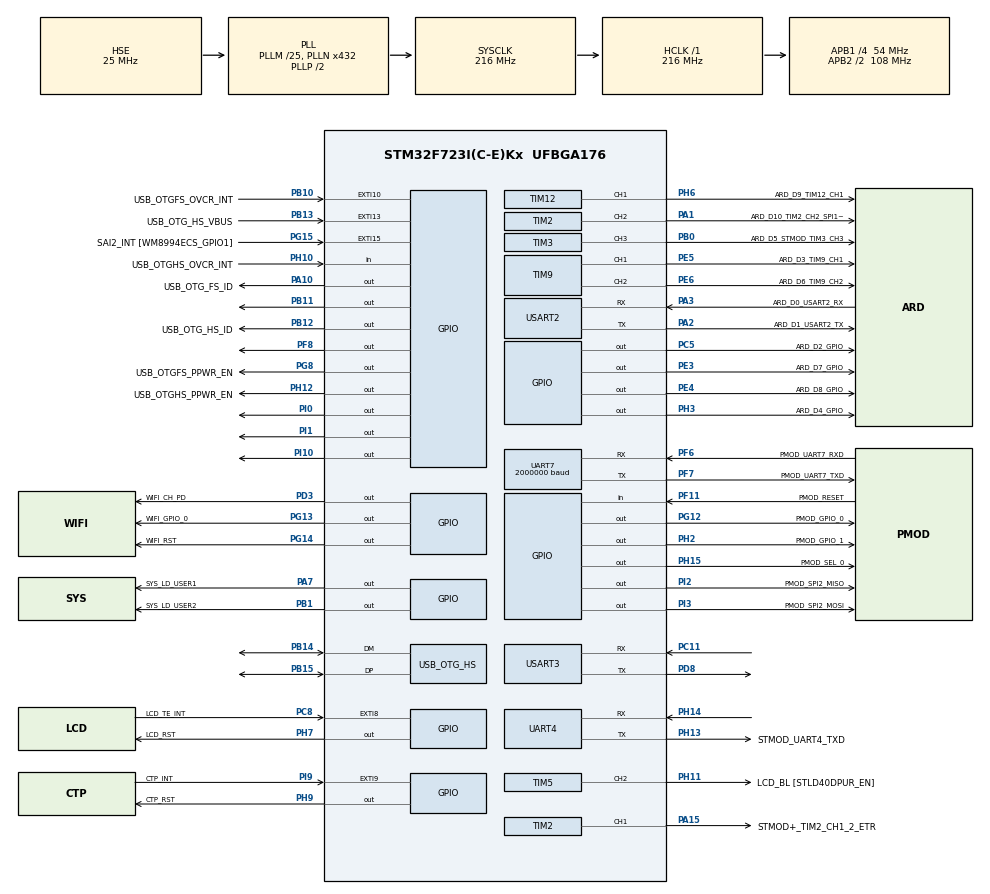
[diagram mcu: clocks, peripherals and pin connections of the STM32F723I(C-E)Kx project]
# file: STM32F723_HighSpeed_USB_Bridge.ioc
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CORTEX_M7.ART_ACCLERATOR_ENABLE=1
CORTEX_M7.CPU_DCache=Enabled
CORTEX_M7.CPU_ICache=Enabled
CORTEX_M7.PREFETCH_ENABLE=1
Dma.Request0=UART7_RX
Dma.Request1=USART3_RX
Dma.Request2=UART4_RX
Dma.Request3=USART2_RX
Dma.UART4_RX.2.Direction=DMA_PERIPH_TO_MEMORY
Dma.UART4_RX.2.FIFOMode=DMA_FIFOMODE_DISABLE
Dma.UART4_RX.2.Instance=DMA1_Stream2
Dma.UART4_RX.2.MemDataAlignment=DMA_MDATAALIGN_BYTE
Dma.UART4_RX.2.MemInc=DMA_MINC_ENABLE
Dma.UART4_RX.2.Mode=DMA_NORMAL
Dma.UART4_RX.2.PeriphDataAlignment=DMA_PDATAALIGN_BYTE
Dma.UART4_RX.2.PeriphInc=DMA_PINC_DISABLE
Dma.UART4_RX.2.Priority=DMA_PRIORITY_MEDIUM
Dma.UART7_RX.0.Direction=DMA_PERIPH_TO_MEMORY
Dma.UART7_RX.0.FIFOMode=DMA_FIFOMODE_ENABLE
Dma.UART7_RX.0.FIFOThreshold=DMA_FIFO_THRESHOLD_FULL
Dma.UART7_RX.0.Instance=DMA1_Stream3
Dma.UART7_RX.0.MemBurst=DMA_MBURST_SINGLE
Dma.UART7_RX.0.MemDataAlignment=DMA_MDATAALIGN_BYTE
Dma.UART7_RX.0.MemInc=DMA_MINC_ENABLE
Dma.UART7_RX.0.Mode=DMA_NORMAL
Dma.UART7_RX.0.PeriphBurst=DMA_PBURST_SINGLE
Dma.UART7_RX.0.PeriphDataAlignment=DMA_PDATAALIGN_BYTE
Dma.UART7_RX.0.PeriphInc=DMA_PINC_DISABLE
Dma.UART7_RX.0.Priority=DMA_PRIORITY_VERY_HIGH
Dma.USART2_RX.3.Direction=DMA_PERIPH_TO_MEMORY
Dma.USART2_RX.3.FIFOMode=DMA_FIFOMODE_DISABLE
Dma.USART2_RX.3.Instance=DMA1_Stream5
Dma.USART2_RX.3.MemDataAlignment=DMA_MDATAALIGN_BYTE
Dma.USART2_RX.3.MemInc=DMA_MINC_ENABLE
Dma.USART2_RX.3.Mode=DMA_NORMAL
Dma.USART2_RX.3.PeriphDataAlignment=DMA_PDATAALIGN_BYTE
Dma.USART2_RX.3.PeriphInc=DMA_PINC_DISABLE
Dma.USART2_RX.3.Priority=DMA_PRIORITY_LOW
Dma.USART3_RX.1.Direction=DMA_PERIPH_TO_MEMORY
Dma.USART3_RX.1.FIFOMode=DMA_FIFOMODE_DISABLE
Dma.USART3_RX.1.Instance=DMA1_Stream1
Dma.USART3_RX.1.MemDataAlignment=DMA_MDATAALIGN_BYTE
Dma.USART3_RX.1.MemInc=DMA_MINC_ENABLE
Dma.USART3_RX.1.Mode=DMA_NORMAL
Dma.USART3_RX.1.PeriphDataAlignment=DMA_PDATAALIGN_BYTE
Dma.USART3_RX.1.PeriphInc=DMA_PINC_DISABLE
Dma.USART3_RX.1.Priority=DMA_PRIORITY_HIGH
Mcu.Family=STM32F7
Mcu.Name=STM32F723I(C-E)Kx
Mcu.Package=UFBGA176
NVIC.DMA1_Stream1_IRQn=true\:1\:1\:true\:false\:true\:false\:false
NVIC.DMA1_Stream2_IRQn=true\:1\:2\:true\:false\:true\:false\:false
NVIC.DMA1_Stream3_IRQn=true\:1\:0\:true\:false\:true\:false\:false
NVIC.DMA1_Stream5_IRQn=true\:1\:3\:true\:false\:true\:false\:false
NVIC.OTG_HS_IRQn=true\:3\:0\:true\:false\:true\:true\:true
NVIC.PriorityGroup=NVIC_PRIORITYGROUP_2
NVIC.TIM1_UP_TIM10_IRQn=true\:3\:3\:true\:false\:true\:true\:true
NVIC.TIM8_TRG_COM_TIM14_IRQn=true\:0\:0\:false\:false\:true\:true\:false
NVIC.TimeBase=TIM1_UP_TIM10_IRQn
NVIC.TimeBaseIP=TIM1
NVIC.UART7_IRQn=true\:2\:0\:true\:false\:true\:true\:false
PA0-WKUP.GPIO_Label=SYS_B_User
PA0-WKUP.Mode=SYS_WakeUp0
PA0-WKUP.Signal=SYS_WKUP1
PA1.GPIO_Label=ARD_D10_TIM2_CH2_SPI1_NSS
PA1.Signal=S_TIM2_CH2
PA10.GPIO_Label=USB_OTG_FS_ID
PA10.Signal=GPIO_Output
PA11.Signal=USB_OTG_FS_DM
PA12.Signal=USB_OTG_FS_DP
PA13.Mode=Serial_Wire
PA13.Signal=SYS_JTMS-SWDIO
PA14.Mode=Serial_Wire
PA14.Signal=SYS_JTCK-SWCLK
PA15.GPIO_Label=STMOD+_TIM2_CH1_2_ETR
PA15.Signal=S_TIM2_CH1_ETR
PA2.GPIO_Label=ARD_D1_USART2_TX
PA2.Mode=Asynchronous
PA2.Signal=USART2_TX
PA3.GPIO_Label=ARD_D0_USART2_RX
PA3.Mode=Asynchronous
PA3.Signal=USART2_RX
PA4.GPIO_Label=ARD_A1
PA4.Signal=ADCx_IN4
PA5.GPIO_Label=ARD_D13_SPI1_SCK
PA5.Signal=SPI1_SCK
PA6.GPIO_Label=ARD_A0
PA6.Signal=ADCx_IN6
PA7.GPIO_Label=SYS_LD_USER1
PA7.Signal=GPIO_Output
PA8.GPIO_Label=CTP_SCL
PA8.Signal=I2C3_SCL
PA9.Signal=USB_OTG_FS_VBUS
PB0.GPIO_Label=ARD_D5_STMOD_TIM3_CH3
PB0.Signal=S_TIM3_CH3
PB1.GPIO_Label=SYS_LD_USER2
PB1.Signal=GPIO_Output
PB10.GPIO_Label=USB_OTGFS_OVCR_INT
PB10.Signal=GPXTI10
PB11.Signal=GPIO_Output
PB12.GPIO_Label=USB_OTG_HS_ID
PB12.Signal=GPIO_Output
PB13.GPIO_Label=USB_OTG_HS_VBUS
PB13.Signal=GPXTI13
PB14.Mode=Internal_Phy_Device
PB14.Signal=USB_OTG_HS_DM
PB15.Mode=Internal_Phy_Device
PB15.Signal=USB_OTG_HS_DP
PB2.GPIO_Label=QSPI_CLK [MX25L51245G_SCLK]
PB2.Signal=QUADSPI_CLK
PB3.GPIO_Label=SYS_STLINK_JTDO_SWO
PB3.Signal=SYS_JTDO-SWO
PB4.GPIO_Label=ARD_D12_SPI1_MISO
PB4.Signal=SPI1_MISO
PB5.GPIO_Label=ARD_D11_TIM3_CH2_SPI1_MOSI
PB5.Signal=SPI1_MOSI
PB6.GPIO_Label=QSPI_NCS [MX25L51245G_CS]
PB6.Signal=QUADSPI_BK1_NCS
PB7.GPIO_Label=NC1
PB7.Signal=FMC_NL
PB8.GPIO_Label=SAI2_I2C1_SCL [WM8994ECS/R_SCLK]
PB8.Signal=I2C1_SCL
PB9.GPIO_Label=SAI2_I2C1_SDA [WM8994ECS_SDA]
PB9.Signal=I2C1_SDA
PC0.GPIO_Label=ARD_A4
PC0.Signal=ADCx_IN10
PC1.GPIO_Label=ARD_A5
PC1.Signal=ADCx_IN11
PC10.GPIO_Label=QSPI_D1 [MX25L51245G_SIO1]
PC10.Signal=QUADSPI_BK1_IO1
PC11.Mode=Asynchronous
PC11.Signal=USART3_RX
PC12.GPIO_Label=UART_TXD_WIFI_RX
PC12.Signal=UART5_TX
PC14-OSC32_IN.Mode=LSE-External-Oscillator
PC14-OSC32_IN.Signal=RCC_OSC32_IN
PC15-OSC32_OUT.Mode=LSE-External-Oscillator
PC15-OSC32_OUT.Signal=RCC_OSC32_OUT
PC2.GPIO_Label=STMOD_SPI2_MISOs
PC2.Signal=SPI2_MISO
PC3.GPIO_Label=STMOD+_SPI2_MOSIs
PC3.Signal=SPI2_MOSI
PC4.GPIO_Label=ARD_A2
PC4.Signal=ADCx_IN14
PC5.GPIO_Label=ARD_D2_GPIO
PC5.Signal=GPIO_Output
PC6.GPIO_Label=VCP_TX [STM32F103CBT6_PA3]
PC6.Signal=USART6_TX
PC7.GPIO_Label=VCP_RX [STM32F103CBT6_PA2]
PC7.Signal=USART6_RX
PC8.GPIO_Label=LCD_TE_INT
PC8.Signal=GPXTI8
PC9.GPIO_Label=QSPI_D0 [MX25L51245G_SIO0]
PC9.Signal=QUADSPI_BK1_IO0
PD0.GPIO_Label=LCD_PSRAM_D2
PD0.Signal=FMC_D2_DA2
PD1.GPIO_Label=LCD_PSRAM_D3
PD1.Signal=FMC_D3_DA3
PD10.GPIO_Label=LCD_PSRAM_D15
PD10.Signal=FMC_D15_DA15
PD11.GPIO_Label=PSRAM_A16
PD11.Signal=FMC_A16_CLE
PD12.GPIO_Label=PSRAM_A17
PD12.Signal=FMC_A17_ALE
PD13.GPIO_Label=QSPI_D3 [MX25L51245G_SIO3]
PD13.Signal=QUADSPI_BK1_IO3
PD14.GPIO_Label=LCD_PSRAM_D0
PD14.Signal=FMC_D0_DA0
PD15.GPIO_Label=LCD_PSRAM_D1
PD15.Signal=FMC_D1_DA1
PD2.GPIO_Label=UART_RXD_WIFI_TX
PD2.Signal=UART5_RX
PD3.GPIO_Label=WIFI_CH_PD
PD3.Signal=GPIO_Output
PD4.GPIO_Label=LCD_PSRAM_NWE
PD4.Signal=FMC_NOE
PD5.GPIO_Label=LCD_PSRAM_NWE
PD5.Signal=FMC_NWE
PD7.GPIO_Label=PSRAM_NE1 [IS66WV51216EBLL_CS1]
PD7.Signal=FMC_NE1
PD8.Mode=Asynchronous
PD8.Signal=USART3_TX
PD9.GPIO_Label=LCD_PSRAM_D14
PD9.Signal=FMC_D14_DA14
PE0.GPIO_Label=PSRAM_NBL0 [IS66WV51216EBLL_LB]
PE0.Signal=FMC_NBL0
PE1.GPIO_Label=PSRAM_NBL1 [IS66WV51216EBLL_UB]
PE1.Signal=FMC_NBL1
PE10.GPIO_Label=LCD_PSRAM_D7
PE10.Signal=FMC_D7_DA7
PE11.GPIO_Label=LCD_PSRAM_D8
PE11.Signal=FMC_D8_DA8
PE12.GPIO_Label=LCD_PSRAM_D9
PE12.Signal=FMC_D9_DA9
PE13.GPIO_Label=LCD_PSRAM_D10
PE13.Signal=FMC_D10_DA10
PE14.GPIO_Label=LCD_PSRAM_D11
PE14.Signal=FMC_D11_DA11
PE15.GPIO_Label=LCD_PSRAM_D12
PE15.Signal=FMC_D12_DA12
PE2.GPIO_Label=QSPI_D2 [MX25L51245G_SIO2]
PE2.Signal=QUADSPI_BK1_IO2
PE3.GPIO_Label=ARD_D7_GPIO
PE3.Signal=GPIO_Output
PE4.GPIO_Label=ARD_D8_GPIO
PE4.Signal=GPIO_Output
PE5.GPIO_Label=ARD_D3_TIM9_CH1
PE5.Signal=S_TIM9_CH1
PE6.GPIO_Label=ARD_D6_TIM9_CH2
PE6.Signal=S_TIM9_CH2
PE7.GPIO_Label=LCD_PSRAM_D4
PE7.Signal=FMC_D4_DA4
PE8.GPIO_Label=LCD_PSRAM_D5
PE8.Signal=FMC_D5_DA5
PE9.GPIO_Label=LCD_PSRAM_D6
PE9.Signal=FMC_D6_DA6
PF0.GPIO_Label=PSRAM_A0
PF0.Signal=FMC_A0
PF1.GPIO_Label=PSRAM_A1
PF1.Signal=FMC_A1
PF10.GPIO_Label=ARD_A3_ADC3_IN8
PF10.Signal=ADC3_IN8
PF11.GPIO_Label=PMOD_RESET
PF11.Signal=GPIO_Input
PF12.GPIO_Label=PSRAM_A6
PF12.Signal=FMC_A6
PF13.GPIO_Label=PSRAM_A7
PF13.Signal=FMC_A7
PF14.GPIO_Label=PSRAM_A8
PF14.Signal=FMC_A8
PF15.GPIO_Label=PSRAM_A9
PF15.Signal=FMC_A9
PF2.GPIO_Label=PSRAM_A2
PF2.Signal=FMC_A2
PF3.GPIO_Label=PSRAM_A3
PF3.Signal=FMC_A3
PF4.GPIO_Label=PSRAM_A4
PF4.Signal=FMC_A4
PF5.GPIO_Label=PSRAM_A5
PF5.Signal=FMC_A5
PF6.GPIO_Label=PMOD_UART7_RXD
PF6.GPIO_PuPd=GPIO_PULLUP
PF6.Mode=Asynchronous
PF6.Signal=UART7_RX
PF7.GPIO_Label=PMOD_UART7_TXD
PF7.GPIO_PuPd=GPIO_PULLUP
PF7.Mode=Asynchronous
PF7.Signal=UART7_TX
PF8.Signal=GPIO_Output
PF9.GPIO_Label=PMOD_UART7_CTS
PF9.Signal=UART7_CTS
PG0.GPIO_Label=PSRAM_A10
PG0.Signal=FMC_A10
PG1.GPIO_Label=PSRAM_A11
PG1.Signal=FMC_A11
PG10.GPIO_Label=SAI2_SD_B [SAI2_SD_B_ADCDAT1]
PG10.Signal=SAI2_SD_B
PG12.GPIO_Label=PMOD_GPIO_0
PG12.Signal=GPIO_Output
PG13.GPIO_Label=WIFI_GPIO_0
PG13.Signal=GPIO_Output
PG14.GPIO_Label=WIFI_RST
PG14.Signal=GPIO_Output
PG15.GPIO_Label=SAI2_INT [WM8994ECS_GPIO1]
PG15.Signal=GPXTI15
PG2.GPIO_Label=PSRAM_A12
PG2.Signal=FMC_A12
PG3.GPIO_Label=PSRAM_A13
PG3.Signal=FMC_A13
PG4.GPIO_Label=PSRAM_A14
PG4.Signal=FMC_A14_BA0
PG5.GPIO_Label=PSRAM_A15
PG5.Signal=FMC_A15_BA1
PG8.GPIO_Label=USB_OTGFS_PPWR_EN
PG8.Signal=GPIO_Output
PG9.GPIO_Label=LCD_NE
PG9.Signal=FMC_NE2
PH0-OSC_IN.Mode=HSE-External-Oscillator
PH0-OSC_IN.Signal=RCC_OSC_IN
PH1-OSC_OUT.Mode=HSE-External-Oscillator
PH1-OSC_OUT.Signal=RCC_OSC_OUT
PH10.GPIO_Label=USB_OTGHS_OVCR_INT
PH10.Signal=GPIO_Input
PH11.GPIO_Label=LCD_BL [STLD40DPUR_EN]
PH11.Signal=S_TIM5_CH2
PH12.GPIO_Label=USB_OTGHS_PPWR_EN
PH12.Signal=GPIO_Output
PH13.GPIO_Label=STMOD_UART4_TXD
PH13.Mode=Asynchronous
PH13.Signal=UART4_TX
PH14.Mode=Asynchronous
PH14.Signal=UART4_RX
PH15.GPIO_Label=PMOD_SEL_0
PH15.PinState=GPIO_PIN_SET
PH15.Signal=GPIO_Output
PH2.GPIO_Label=PMOD_GPIO_1
PH2.Signal=GPIO_Output
PH3.GPIO_Label=ARD_D4_GPIO
PH3.Signal=GPIO_Output
PH4.GPIO_Label=ARD_D15_STMOD_I2C2_SCL
PH4.Signal=I2C2_SCL
PH5.GPIO_Label=ARD_D14_STMOD_I2C2_SDA
PH5.Signal=I2C2_SDA
PH6.GPIO_Label=ARD_D9_TIM12_CH1
PH6.Signal=S_TIM12_CH1
PH7.GPIO_Label=LCD_RST
PH7.Signal=GPIO_Output
PH8.GPIO_Label=CTP_SDA
PH8.Signal=I2C3_SDA
PH9.GPIO_Label=CTP_RST
PH9.Signal=GPIO_Output
PI0.Signal=GPIO_Output
PI1.Signal=GPIO_Output
PI10.Signal=GPIO_Output
PI2.GPIO_Label=PMOD_SPI2_MISO
PI2.Signal=GPIO_Output
PI3.GPIO_Label=PMOD_SPI2_MOSI
PI3.Signal=GPIO_Output
PI4.GPIO_Label=SAI2_MCLK_A [WM8994ECS_MCLK1]
PI4.Signal=SAI2_MCLK_A
PI5.GPIO_Label=SAI2_SCK_A [WM8994ECS_BCLK1]
PI5.Signal=SAI2_SCK_A
PI6.GPIO_Label=SAI2_SD_A [WM8994ECS_DACDAT1]
PI6.Signal=SAI2_SD_A
PI7.GPIO_Label=SAI2_FS_A [WM8994ECS_LRCLK1]
PI7.Signal=SAI2_FS_A
PI9.GPIO_Label=CTP_INT
PI9.Signal=GPXTI9
ProjectManager.HeapSize=0x400
ProjectManager.StackSize=0x400
ProjectManager.TargetToolchain=MDK-ARM V5
RCC.AHBFreq_Value=216000000
RCC.APB1CLKDivider=RCC_HCLK_DIV4
RCC.APB1Freq_Value=54000000
RCC.APB1TimFreq_Value=108000000
RCC.APB2CLKDivider=RCC_HCLK_DIV2
RCC.APB2Freq_Value=108000000
RCC.APB2TimFreq_Value=216000000
RCC.CortexFreq_Value=216000000
RCC.HCLKFreq_Value=216000000
RCC.HSE_VALUE=25000000
RCC.HSI_VALUE=16000000
RCC.PLLM=25
RCC.PLLN=432
RCC.PLLQ=9
RCC.SYSCLKFreq_VALUE=216000000
RCC.SYSCLKSource=RCC_SYSCLKSOURCE_PLLCLK
RCC.UART4CLockSelection=RCC_UART4CLKSOURCE_SYSCLK
RCC.UART5CLockSelection=RCC_UART5CLKSOURCE_SYSCLK
RCC.UART7CLockSelection=RCC_UART7CLKSOURCE_SYSCLK
RCC.USART2CLockSelection=RCC_USART2CLKSOURCE_SYSCLK
RCC.USART6CLockSelection=RCC_USART6CLKSOURCE_SYSCLK
RCC.USBFreq_Value=48000000
RCC.VCOOutputFreq_Value=432000000
REXTPHYHS.GPIO_Label=REXT_OTGPHY
REXTPHYHS.Mode=Internal_Phy_Device
REXTPHYHS.Signal=USB_OTG_HS_REXTPHYHS
SH.ADCx_IN10.0=ADC1_IN10
SH.ADCx_IN10.1=ADC2_IN10
SH.ADCx_IN11.0=ADC1_IN11
SH.ADCx_IN11.1=ADC2_IN11
SH.ADCx_IN14.0=ADC1_IN14
SH.ADCx_IN14.1=ADC2_IN14
SH.ADCx_IN4.0=ADC1_IN4
SH.ADCx_IN4.1=ADC2_IN4
SH.ADCx_IN6.0=ADC1_IN6
SH.ADCx_IN6.1=ADC2_IN6
SH.FMC_A0.0=FMC_A0
SH.FMC_A1.0=FMC_A1
SH.FMC_A10.0=FMC_A10
SH.FMC_A11.0=FMC_A11
SH.FMC_A12.0=FMC_A12
SH.FMC_A13.0=FMC_A13
SH.FMC_A14_BA0.0=FMC_A14
SH.FMC_A15_BA1.0=FMC_A15
SH.FMC_A16_CLE.0=FMC_A16
SH.FMC_A17_ALE.0=FMC_A17
SH.FMC_A2.0=FMC_A2
SH.FMC_A3.0=FMC_A3
SH.FMC_A4.0=FMC_A4
SH.FMC_A5.0=FMC_A5
SH.FMC_A6.0=FMC_A6
SH.FMC_A7.0=FMC_A7
SH.FMC_A8.0=FMC_A8
SH.FMC_A9.0=FMC_A9
SH.FMC_D0_DA0.0=FMC_D0
SH.FMC_D10_DA10.0=FMC_D10
SH.FMC_D11_DA11.0=FMC_D11
SH.FMC_D12_DA12.0=FMC_D12
SH.FMC_D14_DA14.0=FMC_D14
SH.FMC_D15_DA15.0=FMC_D15
SH.FMC_D1_DA1.0=FMC_D1
SH.FMC_D2_DA2.0=FMC_D2
SH.FMC_D3_DA3.0=FMC_D3
SH.FMC_D4_DA4.0=FMC_D4
SH.FMC_D5_DA5.0=FMC_D5
SH.FMC_D6_DA6.0=FMC_D6
SH.FMC_D7_DA7.0=FMC_D7
SH.FMC_D8_DA8.0=FMC_D8
SH.FMC_D9_DA9.0=FMC_D9
SH.FMC_NBL0.0=FMC_NBL0
SH.FMC_NBL1.0=FMC_NBL1
SH.FMC_NL.0=FMC_NL
SH.FMC_NOE.0=FMC_NOE
SH.FMC_NWE.0=FMC_NWE
SH.S_TIM12_CH1.0=TIM12_CH1,PWM Generation1 CH1
SH.S_TIM2_CH1_ETR.0=TIM2_CH1,PWM Generation1 CH1
SH.S_TIM2_CH2.0=TIM2_CH2,PWM Generation2 CH2
SH.S_TIM3_CH3.0=TIM3_CH3,PWM Generation3 CH3
SH.S_TIM5_CH2.0=TIM5_CH2,PWM Generation2 CH2
SH.S_TIM9_CH1.0=TIM9_CH1,PWM Generation1 CH1
SH.S_TIM9_CH2.0=TIM9_CH2,PWM Generation2 CH2
TIM12.Channel-PWM\ Generation1\ CH1=TIM_CHANNEL_1
TIM14.AutoReloadPreload=TIM_AUTORELOAD_PRELOAD_ENABLE
TIM14.Period=1999
TIM14.Prescaler=21599
TIM2.Channel-PWM\ Generation1\ CH1=TIM_CHANNEL_1
TIM2.Channel-PWM\ Generation2\ CH2=TIM_CHANNEL_2
TIM3.Channel-PWM\ Generation3\ CH3=TIM_CHANNEL_3
TIM5.Channel-PWM\ Generation2\ CH2=TIM_CHANNEL_2
TIM9.Channel-PWM\ Generation1\ CH1=TIM_CHANNEL_1
TIM9.Channel-PWM\ Generation2\ CH2=TIM_CHANNEL_2
UART7.BaudRate=2000000
UART7.RxPinLevelInvertParam=UART_ADVFEATURE_RXINV_DISABLE
USART2.VirtualMode-Asynchronous=VM_ASYNC
USART3.VirtualMode-Asynchronous=VM_ASYNC
USB_DEVICE.CLASS_NAME_HS=CDC
USB_DEVICE.USBD_LPM_ENABLED-CDC_HS=0
USB_DEVICE.VirtualMode-CDC_HS=Cdc
USB_DEVICE.VirtualModeHS=Cdc_HS
USB_OTG_HS.VirtualMode=Int_Phy_Device
VP_SYS_VS_tim1.Mode=TIM1
VP_TIM14_VS_ClockSourceINT.Mode=Enable_Timer
VP_USB_DEVICE_VS_USB_DEVICE_CDC_HS.Mode=CDC_HS
board=32F723EDISCOVERY

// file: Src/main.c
/* USER CODE BEGIN Header */
/**
  ******************************************************************************
  * @file           : main.c
  * @brief          : Main program body
  ******************************************************************************
  * This notice applies to any and all portions of this file
  * that are not between comment pairs USER CODE BEGIN and
  * USER CODE END. Other portions of this file, whether
  * inserted by the user or by software development tools
  * are owned by their respective copyright owners.
  *
  * Copyright (c) 2019 STMicroelectronics International N.V.
  * All rights reserved.
  *
  * Redistribution and use in source and binary forms, with or without
  * modification, are permitted, provided that the following conditions are met:
  *
  * 1. Redistribution of source code must retain the above copyright notice,
  *    this list of conditions and the following disclaimer.
  * 2. Redistributions in binary form must reproduce the above copyright notice,
  *    this list of conditions and the following disclaimer in the documentation
  *    and/or other materials provided with the distribution.
  * 3. Neither the name of STMicroelectronics nor the names of other
  *    contributors to this software may be used to endorse or promote products
  *    derived from this software without specific written permission.
  * 4. This software, including modifications and/or derivative works of this
  *    software, must execute solely and exclusively on microcontroller or
  *    microprocessor devices manufactured by or for STMicroelectronics.
  * 5. Redistribution and use of this software other than as permitted under
  *    this license is void and will automatically terminate your rights under
  *    this license.
  *
  * THIS SOFTWARE IS PROVIDED BY STMICROELECTRONICS AND CONTRIBUTORS "AS IS"
  * AND ANY EXPRESS, IMPLIED OR STATUTORY WARRANTIES, INCLUDING, BUT NOT
  * LIMITED TO, THE IMPLIED WARRANTIES OF MERCHANTABILITY, FITNESS FOR A
  * PARTICULAR PURPOSE AND NON-INFRINGEMENT OF THIRD PARTY INTELLECTUAL PROPERTY
  * RIGHTS ARE DISCLAIMED TO THE FULLEST EXTENT PERMITTED BY LAW. IN NO EVENT
  * SHALL STMICROELECTRONICS OR CONTRIBUTORS BE LIABLE FOR ANY DIRECT, INDIRECT,
  * INCIDENTAL, SPECIAL, EXEMPLARY, OR CONSEQUENTIAL DAMAGES (INCLUDING, BUT NOT
  * LIMITED TO, PROCUREMENT OF SUBSTITUTE GOODS OR SERVICES; LOSS OF USE, DATA,
  * OR PROFITS; OR BUSINESS INTERRUPTION) HOWEVER CAUSED AND ON ANY THEORY OF
  * LIABILITY, WHETHER IN CONTRACT, STRICT LIABILITY, OR TORT (INCLUDING
  * NEGLIGENCE OR OTHERWISE) ARISING IN ANY WAY OUT OF THE USE OF THIS SOFTWARE,
  * EVEN IF ADVISED OF THE POSSIBILITY OF SUCH DAMAGE.
  *
  ******************************************************************************
  */
/* USER CODE END Header */

#include "main.h"
#include "usb_device.h"

/* USER CODE BEGIN Includes */
#include "dataMGR.h"
#include "CE32_ioncom.h"
#include "usbd_cdc_if.h"

#define CDC_BUF_SIZE 0x2000
/* USER CODE END Includes */

TIM_HandleTypeDef htim2;
TIM_HandleTypeDef htim3;
TIM_HandleTypeDef htim5;
TIM_HandleTypeDef htim9;
TIM_HandleTypeDef htim12;
TIM_HandleTypeDef htim14;

UART_HandleTypeDef huart4;
UART_HandleTypeDef huart7;
UART_HandleTypeDef huart2;
UART_HandleTypeDef huart3;
DMA_HandleTypeDef hdma_uart4_rx;
DMA_HandleTypeDef hdma_uart7_rx;
DMA_HandleTypeDef hdma_usart2_rx;
DMA_HandleTypeDef hdma_usart3_rx;

/* USER CODE BEGIN PV */
int Bytes;
int Nfail;
int retries;
int WaitCyc;
uint8_t data_buf_RX1[BUF_SIZE];		// This records @ 20kHz x 32CH
uint8_t data_buf_RX2[BUF_SIZE];		// This records @ 20kHz x 32CH
uint8_t data_buf_RX3[BUF_SIZE];		// This records @ 20kHz x 32CH
uint8_t data_buf_RX4[BUF_SIZE];		// This records @ 20kHz x 32CH
uint8_t data_buf_TX[BUF_SIZE];		// This records @ 20kHz x 32CH
uint8_t data_buf_RX_CDC[CDC_BUF_SIZE];
uint16_t misc_DigiSig;
uint8_t rec_cnt;
uint32_t log_cnt;
uint32_t test;
uint32_t LED_CNT;
uint32_t logIdx;	//Index of log in the CE32_systemLog struct
uint32_t filePTR;	//recording pointer location (in 512B unit,real filelen=512*x)
uint32_t updHeader;
dataMGR MGR_TX;
dataMGR MGR_RX1;
dataMGR MGR_RX2;
dataMGR MGR_RX3;
dataMGR MGR_RX4;
dataMGR MGR_CDC;
dataMGR MGR_prev;
dataMGR MGR_misc;
dataMGR MGR_cmd;
uint8_t HD32_sd_temp;

//dataMGR PMGR;
int freq;

const uint16_t RX_size=1000;

struct CE32_IONCOM_Handle IC_handle1;
struct CE32_IONCOM_Handle IC_handle2;
struct CE32_IONCOM_Handle IC_handle3;
struct CE32_IONCOM_Handle IC_handle4;

extern USBD_HandleTypeDef hUsbDeviceFS;
/* USER CODE END PV */

void SystemClock_Config(void);
static void MX_GPIO_Init(void);
static void MX_DMA_Init(void);
static void MX_TIM2_Init(void);
static void MX_TIM3_Init(void);
static void MX_TIM5_Init(void);
static void MX_TIM9_Init(void);
static void MX_TIM12_Init(void);
static void MX_UART7_Init(void);
static void MX_UART4_Init(void);
static void MX_USART2_UART_Init(void);
static void MX_USART3_UART_Init(void);
static void MX_TIM14_Init(void);

int main(void)
{

  /* Enable I-Cache---------------------------------------------------------*/
  SCB_EnableICache();

  /* Enable D-Cache---------------------------------------------------------*/
  SCB_EnableDCache();

  /* MCU Configuration--------------------------------------------------------*/

  /* Reset of all peripherals, Initializes the Flash interface and the Systick. */
  HAL_Init();

  /* Configure the system clock */
  SystemClock_Config();

  /* USER CODE BEGIN SysInit */
	//Must comment MX_USB_Device_init in the initialize code
  /* USER CODE END SysInit */

  /* Initialize all configured peripherals */
  MX_GPIO_Init();
  MX_DMA_Init();
  MX_TIM2_Init();
  MX_TIM3_Init();
  MX_TIM5_Init();
  MX_TIM9_Init();
  MX_TIM12_Init();
  //MX_USB_DEVICE_Init();
  MX_UART7_Init();
  MX_UART4_Init();
  MX_USART2_UART_Init();
  MX_USART3_UART_Init();
  MX_TIM14_Init();
  /* USER CODE BEGIN 2 */
	HAL_GPIO_WritePin(GPIOI,GPIO_PIN_10,GPIO_PIN_SET);//switch Pmode
	HAL_GPIO_WritePin(GPIOH,GPIO_PIN_15,GPIO_PIN_SET);//switch Pmode

	HAL_GPIO_WritePin(GPIOF,GPIO_PIN_8,GPIO_PIN_SET);//LED0
	HAL_GPIO_WritePin(GPIOB,GPIO_PIN_11,GPIO_PIN_SET);//LED1
	HAL_GPIO_WritePin(GPIOG,GPIO_PIN_12,GPIO_PIN_SET);//LED2
	HAL_GPIO_WritePin(GPIOH,GPIO_PIN_2,GPIO_PIN_SET);//LED3
	HAL_Delay(500);
	HAL_GPIO_WritePin(GPIOF,GPIO_PIN_8,GPIO_PIN_RESET);//LED0
	HAL_GPIO_WritePin(GPIOB,GPIO_PIN_11,GPIO_PIN_RESET);//LED1
	HAL_GPIO_WritePin(GPIOG,GPIO_PIN_12,GPIO_PIN_RESET);//LED2
	HAL_GPIO_WritePin(GPIOH,GPIO_PIN_2,GPIO_PIN_RESET);//LED3

	dataMGR_init(&MGR_TX,(char*) data_buf_TX,sizeof(data_buf_TX));					//FIFO setup
	dataMGR_init(&MGR_RX1,(char*) data_buf_RX1,sizeof(data_buf_RX1));					//RX FIFO setup
	dataMGR_init(&MGR_RX2,(char*) data_buf_RX2,sizeof(data_buf_RX2));					//RX FIFO setup
	dataMGR_init(&MGR_RX3,(char*) data_buf_RX3,sizeof(data_buf_RX3));					//RX FIFO setup
	dataMGR_init(&MGR_RX4,(char*) data_buf_RX4,sizeof(data_buf_RX4));					//RX FIFO setup
	dataMGR_init(&MGR_CDC,(char*) data_buf_RX_CDC,sizeof(data_buf_RX_CDC));					//RX FIFO setup

	IC_handle1.DMA_TotalBanks=4;
	IC_handle1.DMA_TransSize=BUF_SIZE/IC_handle1.DMA_TotalBanks;
	IC_handle1.huart=&huart7;
	IC_handle1.IRQn=UART7_IRQn;
	IC_handle1.huart->hdmarx->Instance=DMA1_Stream3;
	IC_handle1.config|=(IONCOM_CONFIG_RXDMA);
	CE32_Ioncom_Init(&IC_handle1,(char*)data_buf_RX1,sizeof(data_buf_RX1),(char*)data_buf_TX,(uint16_t)sizeof(data_buf_TX));
	UART_IONCOM_DMA_Init(&IC_handle1);
	UART_DISABLE(IC_handle1.huart->Instance);					//Disable UART temporarly to avoid interferece with initialization
	IC_handle1.huart->hdmarx->Instance->M0AR = (uint32_t)IC_handle1.RX_MGR.dataPtr; //Set the DMA to be in circular mode and automatic filling the buffer
	IC_handle1.huart->hdmarx->Instance->NDTR = IC_handle1.RX_MGR.dataSize;

	IC_handle2.DMA_TotalBanks=4;
	IC_handle2.DMA_TransSize=BUF_SIZE/IC_handle2.DMA_TotalBanks;
	IC_handle2.huart=&huart3;
	IC_handle2.IRQn=USART3_IRQn;
	IC_handle2.huart->hdmarx->Instance=DMA1_Stream1;
	IC_handle2.config|=(IONCOM_CONFIG_RXDMA);
	CE32_Ioncom_Init(&IC_handle2,(char*)data_buf_RX2,sizeof(data_buf_RX2),(char*)data_buf_TX,(uint16_t)sizeof(data_buf_TX));
	UART_IONCOM_DMA_Init(&IC_handle2);
	UART_DISABLE(IC_handle2.huart->Instance);					//Disable UART temporarly to avoid interferece with initialization
	IC_handle2.huart->hdmarx->Instance->M0AR = (uint32_t)IC_handle2.RX_MGR.dataPtr; //Set the DMA to be in circular mode and automatic filling the buffer
	IC_handle2.huart->hdmarx->Instance->NDTR = IC_handle2.RX_MGR.dataSize;

	IC_handle3.DMA_TotalBanks=4;
	IC_handle3.DMA_TransSize=BUF_SIZE/IC_handle3.DMA_TotalBanks;
	IC_handle3.huart=&huart4;
	IC_handle3.IRQn=UART4_IRQn;
	IC_handle3.huart->hdmarx->Instance=DMA1_Stream2;
	IC_handle3.config|=(IONCOM_CONFIG_RXDMA);
	CE32_Ioncom_Init(&IC_handle3,(char*)data_buf_RX3,sizeof(data_buf_RX3),(char*)data_buf_TX,(uint16_t)sizeof(data_buf_TX));
	UART_IONCOM_DMA_Init(&IC_handle3);
	UART_DISABLE(IC_handle3.huart->Instance);					//Disable UART temporarly to avoid interferece with initialization
	IC_handle3.huart->hdmarx->Instance->M0AR = (uint32_t)IC_handle3.RX_MGR.dataPtr; //Set the DMA to be in circular mode and automatic filling the buffer
	IC_handle3.huart->hdmarx->Instance->NDTR = IC_handle3.RX_MGR.dataSize;

	IC_handle4.DMA_TotalBanks=4;
	IC_handle4.DMA_TransSize=BUF_SIZE/IC_handle4.DMA_TotalBanks;
	IC_handle4.huart=&huart2;
	IC_handle4.IRQn=USART2_IRQn;
	IC_handle4.huart->hdmarx->Instance=DMA1_Stream5;
	IC_handle4.config|=(IONCOM_CONFIG_RXDMA);
	CE32_Ioncom_Init(&IC_handle4,(char*)data_buf_RX4,sizeof(data_buf_RX4),(char*)data_buf_TX,(uint16_t)sizeof(data_buf_TX));
	UART_IONCOM_DMA_Init(&IC_handle4);
	UART_DISABLE(IC_handle4.huart->Instance);					//Disable UART temporarly to avoid interferece with initialization
	IC_handle4.huart->hdmarx->Instance->M0AR = (uint32_t)IC_handle4.RX_MGR.dataPtr; //Set the DMA to be in circular mode and automatic filling the buffer
	IC_handle4.huart->hdmarx->Instance->NDTR = IC_handle4.RX_MGR.dataSize;
	//UART7->CR1|=USART_CR1_RXNEIE;  //Enable RX interrput to receive commands

	MX_USB_DEVICE_Init();

	TIM14->CR1|=TIM_CR1_CEN;	//Enable timer
	TIM14->DIER|=TIM_DIER_UIE;//Enable update interrupt

  /* USER CODE END 2 */

  /* Infinite loop */
  while (1)
  {

    /* USER CODE BEGIN 3 */
		//DIrect mode
		if(IC_handle1.RX_MGR.bufferUsed[0]>=148)
		{
			if((uint8_t)dataMGR_deQueue_byte(&IC_handle1.RX_MGR,0)==0x66)
			{
				if((uint8_t)dataMGR_deQueue_byte(&IC_handle1.RX_MGR,0)==0x55)
				{
					if((uint8_t)dataMGR_deQueue_byte(&IC_handle1.RX_MGR,0)==0x5d)
					{
						if((uint8_t)dataMGR_deQueue_byte(&IC_handle1.RX_MGR,0)==0xd5)
						{
							HAL_GPIO_WritePin(GPIOF,GPIO_PIN_8,GPIO_PIN_SET);
							dataMGR_enQueue_byte(&MGR_CDC,0x66);
							dataMGR_enQueue_byte(&MGR_CDC,0x55);
							dataMGR_enQueue_byte(&MGR_CDC,0x5d);
							dataMGR_enQueue_byte(&MGR_CDC,0x00);
							for(int i=0;i<144;i++)
							{
								while(IC_handle1.RX_MGR.bufferUsed[0]<=0)
								{
								}
								//dataMGR_enQueue_byte(&MGR_CDC,0xAA);
								uint8_t temp=(uint8_t)dataMGR_deQueue_byte(&IC_handle1.RX_MGR,0);
//								if(temp==0)
//								{
//									__nop();
//								}
								dataMGR_enQueue_byte(&MGR_CDC,temp);
							}

							//break;
						}
					}
				}
			}
		}

		if(IC_handle2.RX_MGR.bufferUsed[0]>=148)
		{
			if((uint8_t)dataMGR_deQueue_byte(&IC_handle2.RX_MGR,0)==0x66)
			{
				if((uint8_t)dataMGR_deQueue_byte(&IC_handle2.RX_MGR,0)==0x55)
				{
					if((uint8_t)dataMGR_deQueue_byte(&IC_handle2.RX_MGR,0)==0x5d)
					{
						if((uint8_t)dataMGR_deQueue_byte(&IC_handle2.RX_MGR,0)==0xd5)
						{
							HAL_GPIO_WritePin(GPIOB,GPIO_PIN_11,GPIO_PIN_SET);
							dataMGR_enQueue_byte(&MGR_CDC,0x66);
							dataMGR_enQueue_byte(&MGR_CDC,0x55);
							dataMGR_enQueue_byte(&MGR_CDC,0x5d);
							dataMGR_enQueue_byte(&MGR_CDC,0x01);
							for(int i=0;i<144;i++)
							{
								while(IC_handle2.RX_MGR.bufferUsed[0]<=0)
								{
								}
								dataMGR_enQueue_byte(&MGR_CDC,(uint8_t)dataMGR_deQueue_byte(&IC_handle2.RX_MGR,0));
							}
							//break;

						}
					}
				}
			}
		}

		if(IC_handle3.RX_MGR.bufferUsed[0]>=148)
		{
			if((uint8_t)dataMGR_deQueue_byte(&IC_handle3.RX_MGR,0)==0x66)
			{
				if((uint8_t)dataMGR_deQueue_byte(&IC_handle3.RX_MGR,0)==0x55)
				{
					if((uint8_t)dataMGR_deQueue_byte(&IC_handle3.RX_MGR,0)==0x5d)
					{
						if((uint8_t)dataMGR_deQueue_byte(&IC_handle3.RX_MGR,0)==0xd5)
						{
							HAL_GPIO_WritePin(GPIOG,GPIO_PIN_12,GPIO_PIN_SET);
							dataMGR_enQueue_byte(&MGR_CDC,0x66);
							dataMGR_enQueue_byte(&MGR_CDC,0x55);
							dataMGR_enQueue_byte(&MGR_CDC,0x5d);
							dataMGR_enQueue_byte(&MGR_CDC,0x02);
							for(int i=0;i<144;i++)
							{
								while(IC_handle3.RX_MGR.bufferUsed[0]<=0)
								{
								}
								dataMGR_enQueue_byte(&MGR_CDC,(uint8_t)dataMGR_deQueue_byte(&IC_handle3.RX_MGR,0));
							}

							//break;
						}
					}
				}
			}
		}

		if(IC_handle4.RX_MGR.bufferUsed[0]>=148)
		{
			if((uint8_t)dataMGR_deQueue_byte(&IC_handle4.RX_MGR,0)==0x66)
			{
				if((uint8_t)dataMGR_deQueue_byte(&IC_handle4.RX_MGR,0)==0x55)
				{
					if((uint8_t)dataMGR_deQueue_byte(&IC_handle4.RX_MGR,0)==0x5d)
					{
						if((uint8_t)dataMGR_deQueue_byte(&IC_handle4.RX_MGR,0)==0xd5)
						{
							HAL_GPIO_WritePin(GPIOH,GPIO_PIN_2,GPIO_PIN_SET);
							dataMGR_enQueue_byte(&MGR_CDC,0x66);
							dataMGR_enQueue_byte(&MGR_CDC,0x55);
							dataMGR_enQueue_byte(&MGR_CDC,0x5d);
							dataMGR_enQueue_byte(&MGR_CDC,0x03);
							for(int i=0;i<144;i++)
							{
								while(IC_handle4.RX_MGR.bufferUsed[0]<=0)
								{
								}
								dataMGR_enQueue_byte(&MGR_CDC,(uint8_t)dataMGR_deQueue_byte(&IC_handle4.RX_MGR,0));
							}

							//break;
						}
					}
				}
			}
		}

		if(MGR_CDC.bufferUsed[0]>=CDC_BUF_SIZE/4)
		{
			int ByteToSend=CDC_BUF_SIZE/4;
			if(CDC_Transmit_HS((uint8_t*)(data_buf_RX_CDC+MGR_CDC.outPTR[0]),ByteToSend)==USBD_OK)
			{
				dataMGR_deQueue(&MGR_CDC,ByteToSend,0);
			}
		}
	}
  /* USER CODE END 3 */
}

void SystemClock_Config(void)
{
  RCC_OscInitTypeDef RCC_OscInitStruct = {0};
  RCC_ClkInitTypeDef RCC_ClkInitStruct = {0};
  RCC_PeriphCLKInitTypeDef PeriphClkInitStruct = {0};

  /** Configure LSE Drive Capability
  */
  HAL_PWR_EnableBkUpAccess();
  /** Configure the main internal regulator output voltage
  */
  __HAL_RCC_PWR_CLK_ENABLE();
  __HAL_PWR_VOLTAGESCALING_CONFIG(PWR_REGULATOR_VOLTAGE_SCALE1);
  /** Initializes the CPU, AHB and APB busses clocks
  */
  RCC_OscInitStruct.OscillatorType = RCC_OSCILLATORTYPE_HSE;
  RCC_OscInitStruct.HSEState = RCC_HSE_ON;
  RCC_OscInitStruct.PLL.PLLState = RCC_PLL_ON;
  RCC_OscInitStruct.PLL.PLLSource = RCC_PLLSOURCE_HSE;
  RCC_OscInitStruct.PLL.PLLM = 25;
  RCC_OscInitStruct.PLL.PLLN = 432;
  RCC_OscInitStruct.PLL.PLLP = RCC_PLLP_DIV2;
  RCC_OscInitStruct.PLL.PLLQ = 9;
  if (HAL_RCC_OscConfig(&RCC_OscInitStruct) != HAL_OK)
  {
    Error_Handler();
  }
  /** Activate the Over-Drive mode
  */
  if (HAL_PWREx_EnableOverDrive() != HAL_OK)
  {
    Error_Handler();
  }
  /** Initializes the CPU, AHB and APB busses clocks
  */
  RCC_ClkInitStruct.ClockType = RCC_CLOCKTYPE_HCLK|RCC_CLOCKTYPE_SYSCLK
                              |RCC_CLOCKTYPE_PCLK1|RCC_CLOCKTYPE_PCLK2;
  RCC_ClkInitStruct.SYSCLKSource = RCC_SYSCLKSOURCE_PLLCLK;
  RCC_ClkInitStruct.AHBCLKDivider = RCC_SYSCLK_DIV1;
  RCC_ClkInitStruct.APB1CLKDivider = RCC_HCLK_DIV4;
  RCC_ClkInitStruct.APB2CLKDivider = RCC_HCLK_DIV2;

  if (HAL_RCC_ClockConfig(&RCC_ClkInitStruct, FLASH_LATENCY_7) != HAL_OK)
  {
    Error_Handler();
  }
  PeriphClkInitStruct.PeriphClockSelection = RCC_PERIPHCLK_USART2|RCC_PERIPHCLK_USART3
                              |RCC_PERIPHCLK_UART4|RCC_PERIPHCLK_UART7
                              |RCC_PERIPHCLK_CLK48;
  PeriphClkInitStruct.Usart2ClockSelection = RCC_USART2CLKSOURCE_SYSCLK;
  PeriphClkInitStruct.Usart3ClockSelection = RCC_USART3CLKSOURCE_PCLK1;
  PeriphClkInitStruct.Uart4ClockSelection = RCC_UART4CLKSOURCE_SYSCLK;
  PeriphClkInitStruct.Uart7ClockSelection = RCC_UART7CLKSOURCE_SYSCLK;
  PeriphClkInitStruct.Clk48ClockSelection = RCC_CLK48SOURCE_PLL;
  if (HAL_RCCEx_PeriphCLKConfig(&PeriphClkInitStruct) != HAL_OK)
  {
    Error_Handler();
  }
}

static void MX_TIM2_Init(void)
{

  TIM_MasterConfigTypeDef sMasterConfig = {0};
  TIM_OC_InitTypeDef sConfigOC = {0};

  htim2.Instance = TIM2;
  htim2.Init.Prescaler = 0;
  htim2.Init.CounterMode = TIM_COUNTERMODE_UP;
  htim2.Init.Period = 0;
  htim2.Init.ClockDivision = TIM_CLOCKDIVISION_DIV1;
  htim2.Init.AutoReloadPreload = TIM_AUTORELOAD_PRELOAD_DISABLE;
  if (HAL_TIM_PWM_Init(&htim2) != HAL_OK)
  {
    Error_Handler();
  }
  sMasterConfig.MasterOutputTrigger = TIM_TRGO_RESET;
  sMasterConfig.MasterSlaveMode = TIM_MASTERSLAVEMODE_DISABLE;
  if (HAL_TIMEx_MasterConfigSynchronization(&htim2, &sMasterConfig) != HAL_OK)
  {
    Error_Handler();
  }
  sConfigOC.OCMode = TIM_OCMODE_PWM1;
  sConfigOC.Pulse = 0;
  sConfigOC.OCPolarity = TIM_OCPOLARITY_HIGH;
  sConfigOC.OCFastMode = TIM_OCFAST_DISABLE;
  if (HAL_TIM_PWM_ConfigChannel(&htim2, &sConfigOC, TIM_CHANNEL_1) != HAL_OK)
  {
    Error_Handler();
  }
  if (HAL_TIM_PWM_ConfigChannel(&htim2, &sConfigOC, TIM_CHANNEL_2) != HAL_OK)
  {
    Error_Handler();
  }
  HAL_TIM_MspPostInit(&htim2);

}

static void MX_TIM3_Init(void)
{

  TIM_MasterConfigTypeDef sMasterConfig = {0};
  TIM_OC_InitTypeDef sConfigOC = {0};

  htim3.Instance = TIM3;
  htim3.Init.Prescaler = 0;
  htim3.Init.CounterMode = TIM_COUNTERMODE_UP;
  htim3.Init.Period = 0;
  htim3.Init.ClockDivision = TIM_CLOCKDIVISION_DIV1;
  htim3.Init.AutoReloadPreload = TIM_AUTORELOAD_PRELOAD_DISABLE;
  if (HAL_TIM_PWM_Init(&htim3) != HAL_OK)
  {
    Error_Handler();
  }
  sMasterConfig.MasterOutputTrigger = TIM_TRGO_RESET;
  sMasterConfig.MasterSlaveMode = TIM_MASTERSLAVEMODE_DISABLE;
  if (HAL_TIMEx_MasterConfigSynchronization(&htim3, &sMasterConfig) != HAL_OK)
  {
    Error_Handler();
  }
  sConfigOC.OCMode = TIM_OCMODE_PWM1;
  sConfigOC.Pulse = 0;
  sConfigOC.OCPolarity = TIM_OCPOLARITY_HIGH;
  sConfigOC.OCFastMode = TIM_OCFAST_DISABLE;
  if (HAL_TIM_PWM_ConfigChannel(&htim3, &sConfigOC, TIM_CHANNEL_3) != HAL_OK)
  {
    Error_Handler();
  }
  HAL_TIM_MspPostInit(&htim3);

}

static void MX_TIM5_Init(void)
{

  TIM_MasterConfigTypeDef sMasterConfig = {0};
  TIM_OC_InitTypeDef sConfigOC = {0};

  htim5.Instance = TIM5;
  htim5.Init.Prescaler = 0;
  htim5.Init.CounterMode = TIM_COUNTERMODE_UP;
  htim5.Init.Period = 0;
  htim5.Init.ClockDivision = TIM_CLOCKDIVISION_DIV1;
  htim5.Init.AutoReloadPreload = TIM_AUTORELOAD_PRELOAD_DISABLE;
  if (HAL_TIM_PWM_Init(&htim5) != HAL_OK)
  {
    Error_Handler();
  }
  sMasterConfig.MasterOutputTrigger = TIM_TRGO_RESET;
  sMasterConfig.MasterSlaveMode = TIM_MASTERSLAVEMODE_DISABLE;
  if (HAL_TIMEx_MasterConfigSynchronization(&htim5, &sMasterConfig) != HAL_OK)
  {
    Error_Handler();
  }
  sConfigOC.OCMode = TIM_OCMODE_PWM1;
  sConfigOC.Pulse = 0;
  sConfigOC.OCPolarity = TIM_OCPOLARITY_HIGH;
  sConfigOC.OCFastMode = TIM_OCFAST_DISABLE;
  if (HAL_TIM_PWM_ConfigChannel(&htim5, &sConfigOC, TIM_CHANNEL_2) != HAL_OK)
  {
    Error_Handler();
  }
  HAL_TIM_MspPostInit(&htim5);

}

static void MX_TIM9_Init(void)
{

  TIM_OC_InitTypeDef sConfigOC = {0};

  htim9.Instance = TIM9;
  htim9.Init.Prescaler = 0;
  htim9.Init.CounterMode = TIM_COUNTERMODE_UP;
  htim9.Init.Period = 0;
  htim9.Init.ClockDivision = TIM_CLOCKDIVISION_DIV1;
  htim9.Init.AutoReloadPreload = TIM_AUTORELOAD_PRELOAD_DISABLE;
  if (HAL_TIM_PWM_Init(&htim9) != HAL_OK)
  {
    Error_Handler();
  }
  sConfigOC.OCMode = TIM_OCMODE_PWM1;
  sConfigOC.Pulse = 0;
  sConfigOC.OCPolarity = TIM_OCPOLARITY_HIGH;
  sConfigOC.OCFastMode = TIM_OCFAST_DISABLE;
  if (HAL_TIM_PWM_ConfigChannel(&htim9, &sConfigOC, TIM_CHANNEL_1) != HAL_OK)
  {
    Error_Handler();
  }
  if (HAL_TIM_PWM_ConfigChannel(&htim9, &sConfigOC, TIM_CHANNEL_2) != HAL_OK)
  {
    Error_Handler();
  }
  HAL_TIM_MspPostInit(&htim9);

}

static void MX_TIM12_Init(void)
{

  TIM_OC_InitTypeDef sConfigOC = {0};

  htim12.Instance = TIM12;
  htim12.Init.Prescaler = 0;
  htim12.Init.CounterMode = TIM_COUNTERMODE_UP;
  htim12.Init.Period = 0;
  htim12.Init.ClockDivision = TIM_CLOCKDIVISION_DIV1;
  htim12.Init.AutoReloadPreload = TIM_AUTORELOAD_PRELOAD_DISABLE;
  if (HAL_TIM_PWM_Init(&htim12) != HAL_OK)
  {
    Error_Handler();
  }
  sConfigOC.OCMode = TIM_OCMODE_PWM1;
  sConfigOC.Pulse = 0;
  sConfigOC.OCPolarity = TIM_OCPOLARITY_HIGH;
  sConfigOC.OCFastMode = TIM_OCFAST_DISABLE;
  if (HAL_TIM_PWM_ConfigChannel(&htim12, &sConfigOC, TIM_CHANNEL_1) != HAL_OK)
  {
    Error_Handler();
  }
  HAL_TIM_MspPostInit(&htim12);

}

static void MX_TIM14_Init(void)
{

  htim14.Instance = TIM14;
  htim14.Init.Prescaler = 21599;
  htim14.Init.CounterMode = TIM_COUNTERMODE_UP;
  htim14.Init.Period = 1999;
  htim14.Init.ClockDivision = TIM_CLOCKDIVISION_DIV1;
  htim14.Init.AutoReloadPreload = TIM_AUTORELOAD_PRELOAD_ENABLE;
  if (HAL_TIM_Base_Init(&htim14) != HAL_OK)
  {
    Error_Handler();
  }

}

static void MX_UART4_Init(void)
{

  huart4.Instance = UART4;
  huart4.Init.BaudRate = 115200;
  huart4.Init.WordLength = UART_WORDLENGTH_8B;
  huart4.Init.StopBits = UART_STOPBITS_1;
  huart4.Init.Parity = UART_PARITY_NONE;
  huart4.Init.Mode = UART_MODE_TX_RX;
  huart4.Init.HwFlowCtl = UART_HWCONTROL_NONE;
  huart4.Init.OverSampling = UART_OVERSAMPLING_16;
  huart4.Init.OneBitSampling = UART_ONE_BIT_SAMPLE_DISABLE;
  huart4.AdvancedInit.AdvFeatureInit = UART_ADVFEATURE_NO_INIT;
  if (HAL_UART_Init(&huart4) != HAL_OK)
  {
    Error_Handler();
  }

}

static void MX_UART7_Init(void)
{

  huart7.Instance = UART7;
  huart7.Init.BaudRate = 2000000;
  huart7.Init.WordLength = UART_WORDLENGTH_8B;
  huart7.Init.StopBits = UART_STOPBITS_1;
  huart7.Init.Parity = UART_PARITY_NONE;
  huart7.Init.Mode = UART_MODE_TX_RX;
  huart7.Init.HwFlowCtl = UART_HWCONTROL_NONE;
  huart7.Init.OverSampling = UART_OVERSAMPLING_16;
  huart7.Init.OneBitSampling = UART_ONE_BIT_SAMPLE_DISABLE;
  huart7.AdvancedInit.AdvFeatureInit = UART_ADVFEATURE_NO_INIT;
  if (HAL_UART_Init(&huart7) != HAL_OK)
  {
    Error_Handler();
  }

}

static void MX_USART2_UART_Init(void)
{

  huart2.Instance = USART2;
  huart2.Init.BaudRate = 115200;
  huart2.Init.WordLength = UART_WORDLENGTH_8B;
  huart2.Init.StopBits = UART_STOPBITS_1;
  huart2.Init.Parity = UART_PARITY_NONE;
  huart2.Init.Mode = UART_MODE_TX_RX;
  huart2.Init.HwFlowCtl = UART_HWCONTROL_NONE;
  huart2.Init.OverSampling = UART_OVERSAMPLING_16;
  huart2.Init.OneBitSampling = UART_ONE_BIT_SAMPLE_DISABLE;
  huart2.AdvancedInit.AdvFeatureInit = UART_ADVFEATURE_NO_INIT;
  if (HAL_UART_Init(&huart2) != HAL_OK)
  {
    Error_Handler();
  }

}

static void MX_USART3_UART_Init(void)
{

  huart3.Instance = USART3;
  huart3.Init.BaudRate = 115200;
  huart3.Init.WordLength = UART_WORDLENGTH_8B;
  huart3.Init.StopBits = UART_STOPBITS_1;
  huart3.Init.Parity = UART_PARITY_NONE;
  huart3.Init.Mode = UART_MODE_TX_RX;
  huart3.Init.HwFlowCtl = UART_HWCONTROL_NONE;
  huart3.Init.OverSampling = UART_OVERSAMPLING_16;
  huart3.Init.OneBitSampling = UART_ONE_BIT_SAMPLE_DISABLE;
  huart3.AdvancedInit.AdvFeatureInit = UART_ADVFEATURE_NO_INIT;
  if (HAL_UART_Init(&huart3) != HAL_OK)
  {
    Error_Handler();
  }

}

static void MX_DMA_Init(void)
{
  /* DMA controller clock enable */
  __HAL_RCC_DMA1_CLK_ENABLE();

  /* DMA interrupt init */
  /* DMA1_Stream1_IRQn interrupt configuration */
  HAL_NVIC_SetPriority(DMA1_Stream1_IRQn, 1, 1);
  HAL_NVIC_EnableIRQ(DMA1_Stream1_IRQn);
  /* DMA1_Stream2_IRQn interrupt configuration */
  HAL_NVIC_SetPriority(DMA1_Stream2_IRQn, 1, 2);
  HAL_NVIC_EnableIRQ(DMA1_Stream2_IRQn);
  /* DMA1_Stream3_IRQn interrupt configuration */
  HAL_NVIC_SetPriority(DMA1_Stream3_IRQn, 1, 0);
  HAL_NVIC_EnableIRQ(DMA1_Stream3_IRQn);
  /* DMA1_Stream5_IRQn interrupt configuration */
  HAL_NVIC_SetPriority(DMA1_Stream5_IRQn, 1, 3);
  HAL_NVIC_EnableIRQ(DMA1_Stream5_IRQn);

}

static void MX_GPIO_Init(void)
{
  GPIO_InitTypeDef GPIO_InitStruct = {0};

  /* GPIO Ports Clock Enable */
  __HAL_RCC_GPIOE_CLK_ENABLE();
  __HAL_RCC_GPIOB_CLK_ENABLE();
  __HAL_RCC_GPIOG_CLK_ENABLE();
  __HAL_RCC_GPIOD_CLK_ENABLE();
  __HAL_RCC_GPIOC_CLK_ENABLE();
  __HAL_RCC_GPIOA_CLK_ENABLE();
  __HAL_RCC_GPIOI_CLK_ENABLE();
  __HAL_RCC_GPIOH_CLK_ENABLE();
  __HAL_RCC_GPIOF_CLK_ENABLE();

  /*Configure GPIO pin Output Level */
  HAL_GPIO_WritePin(GPIOE, ARD_D7_GPIO_Pin|ARD_D8_GPIO_Pin, GPIO_PIN_RESET);

  /*Configure GPIO pin Output Level */
  HAL_GPIO_WritePin(GPIOG, WIFI_RST_Pin|WIFI_GPIO_0_Pin|PMOD_GPIO_0_Pin|USB_OTGFS_PPWR_EN_Pin, GPIO_PIN_RESET);

  /*Configure GPIO pin Output Level */
  HAL_GPIO_WritePin(GPIOI, PMOD_SPI2_MOSI_Pin|PMOD_SPI2_MISO_Pin|GPIO_PIN_1|GPIO_PIN_10
                          |GPIO_PIN_0, GPIO_PIN_RESET);

  /*Configure GPIO pin Output Level */
  HAL_GPIO_WritePin(WIFI_CH_PD_GPIO_Port, WIFI_CH_PD_Pin, GPIO_PIN_RESET);

  /*Configure GPIO pin Output Level */
  HAL_GPIO_WritePin(PMOD_SEL_0_GPIO_Port, PMOD_SEL_0_Pin, GPIO_PIN_SET);

  /*Configure GPIO pin Output Level */
  HAL_GPIO_WritePin(GPIOA, USB_OTG_FS_ID_Pin|SYS_LD_USER1_Pin, GPIO_PIN_RESET);

  /*Configure GPIO pin Output Level */
  HAL_GPIO_WritePin(GPIOH, PMOD_GPIO_1_Pin|ARD_D4_GPIO_Pin|USB_OTGHS_PPWR_EN_Pin|CTP_RST_Pin
                          |LCD_RST_Pin, GPIO_PIN_RESET);

  /*Configure GPIO pin Output Level */
  HAL_GPIO_WritePin(GPIOF, GPIO_PIN_8, GPIO_PIN_RESET);

  /*Configure GPIO pin Output Level */
  HAL_GPIO_WritePin(ARD_D2_GPIO_GPIO_Port, ARD_D2_GPIO_Pin, GPIO_PIN_RESET);

  /*Configure GPIO pin Output Level */
  HAL_GPIO_WritePin(GPIOB, USB_OTG_HS_ID_Pin|SYS_LD_USER2_Pin|GPIO_PIN_11, GPIO_PIN_RESET);

  /*Configure GPIO pins : ARD_D7_GPIO_Pin ARD_D8_GPIO_Pin */
  GPIO_InitStruct.Pin = ARD_D7_GPIO_Pin|ARD_D8_GPIO_Pin;
  GPIO_InitStruct.Mode = GPIO_MODE_OUTPUT_PP;
  GPIO_InitStruct.Pull = GPIO_NOPULL;
  GPIO_InitStruct.Speed = GPIO_SPEED_FREQ_LOW;
  HAL_GPIO_Init(GPIOE, &GPIO_InitStruct);

  /*Configure GPIO pin : QSPI_D2_Pin */
  GPIO_InitStruct.Pin = QSPI_D2_Pin;
  GPIO_InitStruct.Mode = GPIO_MODE_AF_PP;
  GPIO_InitStruct.Pull = GPIO_NOPULL;
  GPIO_InitStruct.Speed = GPIO_SPEED_FREQ_VERY_HIGH;
  GPIO_InitStruct.Alternate = GPIO_AF9_QUADSPI;
  HAL_GPIO_Init(QSPI_D2_GPIO_Port, &GPIO_InitStruct);

  /*Configure GPIO pins : PSRAM_NBL1_Pin PSRAM_NBL0_Pin LCD_PSRAM_D10_Pin LCD_PSRAM_D5_Pin
                           LCD_PSRAM_D6_Pin LCD_PSRAM_D8_Pin LCD_PSRAM_D11_Pin LCD_PSRAM_D4_Pin
                           LCD_PSRAM_D7_Pin LCD_PSRAM_D9_Pin LCD_PSRAM_D12_Pin */
  GPIO_InitStruct.Pin = PSRAM_NBL1_Pin|PSRAM_NBL0_Pin|LCD_PSRAM_D10_Pin|LCD_PSRAM_D5_Pin
                          |LCD_PSRAM_D6_Pin|LCD_PSRAM_D8_Pin|LCD_PSRAM_D11_Pin|LCD_PSRAM_D4_Pin
                          |LCD_PSRAM_D7_Pin|LCD_PSRAM_D9_Pin|LCD_PSRAM_D12_Pin;
  GPIO_InitStruct.Mode = GPIO_MODE_AF_PP;
  GPIO_InitStruct.Pull = GPIO_NOPULL;
  GPIO_InitStruct.Speed = GPIO_SPEED_FREQ_VERY_HIGH;
  GPIO_InitStruct.Alternate = GPIO_AF12_FMC;
  HAL_GPIO_Init(GPIOE, &GPIO_InitStruct);

  /*Configure GPIO pins : SAI2_I2C1_SCL_Pin SAI2_I2C1_SDA_Pin */
  GPIO_InitStruct.Pin = SAI2_I2C1_SCL_Pin|SAI2_I2C1_SDA_Pin;
  GPIO_InitStruct.Mode = GPIO_MODE_AF_OD;
  GPIO_InitStruct.Pull = GPIO_PULLUP;
  GPIO_InitStruct.Speed = GPIO_SPEED_FREQ_VERY_HIGH;
  GPIO_InitStruct.Alternate = GPIO_AF4_I2C1;
  HAL_GPIO_Init(GPIOB, &GPIO_InitStruct);

  /*Configure GPIO pins : ARD_D11_TIM3_CH2_SPI1_MOSI_Pin ARD_D12_SPI1_MISO_Pin */
  GPIO_InitStruct.Pin = ARD_D11_TIM3_CH2_SPI1_MOSI_Pin|ARD_D12_SPI1_MISO_Pin;
  GPIO_InitStruct.Mode = GPIO_MODE_AF_PP;
  GPIO_InitStruct.Pull = GPIO_NOPULL;
  GPIO_InitStruct.Speed = GPIO_SPEED_FREQ_VERY_HIGH;
  GPIO_InitStruct.Alternate = GPIO_AF5_SPI1;
  HAL_GPIO_Init(GPIOB, &GPIO_InitStruct);

  /*Configure GPIO pins : WIFI_RST_Pin WIFI_GPIO_0_Pin PMOD_GPIO_0_Pin USB_OTGFS_PPWR_EN_Pin */
  GPIO_InitStruct.Pin = WIFI_RST_Pin|WIFI_GPIO_0_Pin|PMOD_GPIO_0_Pin|USB_OTGFS_PPWR_EN_Pin;
  GPIO_InitStruct.Mode = GPIO_MODE_OUTPUT_PP;
  GPIO_InitStruct.Pull = GPIO_NOPULL;
  GPIO_InitStruct.Speed = GPIO_SPEED_FREQ_LOW;
  HAL_GPIO_Init(GPIOG, &GPIO_InitStruct);

  /*Configure GPIO pins : PSRAM_NE1_Pin LCD_PSRAM_D2_Pin LCD_PSRAM_NWE_Pin LCD_PSRAM_D3_Pin
                           LCD_PSRAM_NWED4_Pin LCD_PSRAM_D1_Pin LCD_PSRAM_D0_Pin PSRAM_A17_Pin
                           PSRAM_A16_Pin LCD_PSRAM_D15_Pin LCD_PSRAM_D14_Pin */
  GPIO_InitStruct.Pin = PSRAM_NE1_Pin|LCD_PSRAM_D2_Pin|LCD_PSRAM_NWE_Pin|LCD_PSRAM_D3_Pin
                          |LCD_PSRAM_NWED4_Pin|LCD_PSRAM_D1_Pin|LCD_PSRAM_D0_Pin|PSRAM_A17_Pin
                          |PSRAM_A16_Pin|LCD_PSRAM_D15_Pin|LCD_PSRAM_D14_Pin;
  GPIO_InitStruct.Mode = GPIO_MODE_AF_PP;
  GPIO_InitStruct.Pull = GPIO_NOPULL;
  GPIO_InitStruct.Speed = GPIO_SPEED_FREQ_VERY_HIGH;
  GPIO_InitStruct.Alternate = GPIO_AF12_FMC;
  HAL_GPIO_Init(GPIOD, &GPIO_InitStruct);

  /*Configure GPIO pin : UART_TXD_WIFI_RX_Pin */
  GPIO_InitStruct.Pin = UART_TXD_WIFI_RX_Pin;
  GPIO_InitStruct.Mode = GPIO_MODE_AF_PP;
  GPIO_InitStruct.Pull = GPIO_NOPULL;
  GPIO_InitStruct.Speed = GPIO_SPEED_FREQ_VERY_HIGH;
  GPIO_InitStruct.Alternate = GPIO_AF8_UART5;
  HAL_GPIO_Init(UART_TXD_WIFI_RX_GPIO_Port, &GPIO_InitStruct);

  /*Configure GPIO pin : NC1_Pin */
  GPIO_InitStruct.Pin = NC1_Pin;
  GPIO_InitStruct.Mode = GPIO_MODE_AF_PP;
  GPIO_InitStruct.Pull = GPIO_NOPULL;
  GPIO_InitStruct.Speed = GPIO_SPEED_FREQ_VERY_HIGH;
  GPIO_InitStruct.Alternate = GPIO_AF12_FMC;
  HAL_GPIO_Init(NC1_GPIO_Port, &GPIO_InitStruct);

  /*Configure GPIO pin : QSPI_NCS_Pin */
  GPIO_InitStruct.Pin = QSPI_NCS_Pin;
  GPIO_InitStruct.Mode = GPIO_MODE_AF_PP;
  GPIO_InitStruct.Pull = GPIO_NOPULL;
  GPIO_InitStruct.Speed = GPIO_SPEED_FREQ_VERY_HIGH;
  GPIO_InitStruct.Alternate = GPIO_AF10_QUADSPI;
  HAL_GPIO_Init(QSPI_NCS_GPIO_Port, &GPIO_InitStruct);

  /*Configure GPIO pin : SAI2_INT_Pin */
  GPIO_InitStruct.Pin = SAI2_INT_Pin;
  GPIO_InitStruct.Mode = GPIO_MODE_IT_RISING;
  GPIO_InitStruct.Pull = GPIO_NOPULL;
  HAL_GPIO_Init(SAI2_INT_GPIO_Port, &GPIO_InitStruct);

  /*Configure GPIO pin : SAI2_SD_B_Pin */
  GPIO_InitStruct.Pin = SAI2_SD_B_Pin;
  GPIO_InitStruct.Mode = GPIO_MODE_AF_PP;
  GPIO_InitStruct.Pull = GPIO_NOPULL;
  GPIO_InitStruct.Speed = GPIO_SPEED_FREQ_LOW;
  GPIO_InitStruct.Alternate = GPIO_AF10_SAI2;
  HAL_GPIO_Init(SAI2_SD_B_GPIO_Port, &GPIO_InitStruct);

  /*Configure GPIO pins : QSPI_D1_Pin QSPI_D0_Pin */
  GPIO_InitStruct.Pin = QSPI_D1_Pin|QSPI_D0_Pin;
  GPIO_InitStruct.Mode = GPIO_MODE_AF_PP;
  GPIO_InitStruct.Pull = GPIO_NOPULL;
  GPIO_InitStruct.Speed = GPIO_SPEED_FREQ_VERY_HIGH;
  GPIO_InitStruct.Alternate = GPIO_AF9_QUADSPI;
  HAL_GPIO_Init(GPIOC, &GPIO_InitStruct);

  /*Configure GPIO pins : PA12 PA11 */
  GPIO_InitStruct.Pin = GPIO_PIN_12|GPIO_PIN_11;
  GPIO_InitStruct.Mode = GPIO_MODE_AF_PP;
  GPIO_InitStruct.Pull = GPIO_NOPULL;
  GPIO_InitStruct.Speed = GPIO_SPEED_FREQ_VERY_HIGH;
  GPIO_InitStruct.Alternate = GPIO_AF10_OTG_FS;
  HAL_GPIO_Init(GPIOA, &GPIO_InitStruct);

  /*Configure GPIO pins : SAI2_FS_A_Pin SAI2_SD_A_Pin SAI2_SCK_A_Pin SAI2_MCLK_A_Pin */
  GPIO_InitStruct.Pin = SAI2_FS_A_Pin|SAI2_SD_A_Pin|SAI2_SCK_A_Pin|SAI2_MCLK_A_Pin;
  GPIO_InitStruct.Mode = GPIO_MODE_AF_PP;
  GPIO_InitStruct.Pull = GPIO_NOPULL;
  GPIO_InitStruct.Speed = GPIO_SPEED_FREQ_LOW;
  GPIO_InitStruct.Alternate = GPIO_AF10_SAI2;
  HAL_GPIO_Init(GPIOI, &GPIO_InitStruct);

  /*Configure GPIO pins : LCD_NE_Pin PSRAM_A15_Pin PSRAM_A14_Pin PSRAM_A13_Pin
                           PSRAM_A12_Pin PSRAM_A11_Pin PSRAM_A10_Pin */
  GPIO_InitStruct.Pin = LCD_NE_Pin|PSRAM_A15_Pin|PSRAM_A14_Pin|PSRAM_A13_Pin
                          |PSRAM_A12_Pin|PSRAM_A11_Pin|PSRAM_A10_Pin;
  GPIO_InitStruct.Mode = GPIO_MODE_AF_PP;
  GPIO_InitStruct.Pull = GPIO_NOPULL;
  GPIO_InitStruct.Speed = GPIO_SPEED_FREQ_VERY_HIGH;
  GPIO_InitStruct.Alternate = GPIO_AF12_FMC;
  HAL_GPIO_Init(GPIOG, &GPIO_InitStruct);

  /*Configure GPIO pins : PMOD_SPI2_MOSI_Pin PMOD_SPI2_MISO_Pin PI1 PI10
                           PI0 */
  GPIO_InitStruct.Pin = PMOD_SPI2_MOSI_Pin|PMOD_SPI2_MISO_Pin|GPIO_PIN_1|GPIO_PIN_10
                          |GPIO_PIN_0;
  GPIO_InitStruct.Mode = GPIO_MODE_OUTPUT_PP;
  GPIO_InitStruct.Pull = GPIO_NOPULL;
  GPIO_InitStruct.Speed = GPIO_SPEED_FREQ_LOW;
  HAL_GPIO_Init(GPIOI, &GPIO_InitStruct);

  /*Configure GPIO pin : CTP_INT_Pin */
  GPIO_InitStruct.Pin = CTP_INT_Pin;
  GPIO_InitStruct.Mode = GPIO_MODE_IT_RISING;
  GPIO_InitStruct.Pull = GPIO_NOPULL;
  HAL_GPIO_Init(CTP_INT_GPIO_Port, &GPIO_InitStruct);

  /*Configure GPIO pin : WIFI_CH_PD_Pin */
  GPIO_InitStruct.Pin = WIFI_CH_PD_Pin;
  GPIO_InitStruct.Mode = GPIO_MODE_OUTPUT_PP;
  GPIO_InitStruct.Pull = GPIO_NOPULL;
  GPIO_InitStruct.Speed = GPIO_SPEED_FREQ_LOW;
  HAL_GPIO_Init(WIFI_CH_PD_GPIO_Port, &GPIO_InitStruct);

  /*Configure GPIO pin : UART_RXD_WIFI_TX_Pin */
  GPIO_InitStruct.Pin = UART_RXD_WIFI_TX_Pin;
  GPIO_InitStruct.Mode = GPIO_MODE_AF_PP;
  GPIO_InitStruct.Pull = GPIO_NOPULL;
  GPIO_InitStruct.Speed = GPIO_SPEED_FREQ_VERY_HIGH;
  GPIO_InitStruct.Alternate = GPIO_AF8_UART5;
  HAL_GPIO_Init(UART_RXD_WIFI_TX_GPIO_Port, &GPIO_InitStruct);

  /*Configure GPIO pins : PMOD_SEL_0_Pin PMOD_GPIO_1_Pin ARD_D4_GPIO_Pin USB_OTGHS_PPWR_EN_Pin
                           CTP_RST_Pin LCD_RST_Pin */
  GPIO_InitStruct.Pin = PMOD_SEL_0_Pin|PMOD_GPIO_1_Pin|ARD_D4_GPIO_Pin|USB_OTGHS_PPWR_EN_Pin
                          |CTP_RST_Pin|LCD_RST_Pin;
  GPIO_InitStruct.Mode = GPIO_MODE_OUTPUT_PP;
  GPIO_InitStruct.Pull = GPIO_NOPULL;
  GPIO_InitStruct.Speed = GPIO_SPEED_FREQ_LOW;
  HAL_GPIO_Init(GPIOH, &GPIO_InitStruct);

  /*Configure GPIO pins : USB_OTG_FS_ID_Pin SYS_LD_USER1_Pin */
  GPIO_InitStruct.Pin = USB_OTG_FS_ID_Pin|SYS_LD_USER1_Pin;
  GPIO_InitStruct.Mode = GPIO_MODE_OUTPUT_PP;
  GPIO_InitStruct.Pull = GPIO_NOPULL;
  GPIO_InitStruct.Speed = GPIO_SPEED_FREQ_LOW;
  HAL_GPIO_Init(GPIOA, &GPIO_InitStruct);

  /*Configure GPIO pins : PSRAM_A0_Pin PSRAM_A2_Pin PSRAM_A1_Pin PSRAM_A3_Pin
                           PSRAM_A4_Pin PSRAM_A5_Pin PSRAM_A7_Pin PSRAM_A6_Pin
                           PSRAM_A9_Pin PSRAM_A8_Pin */
  GPIO_InitStruct.Pin = PSRAM_A0_Pin|PSRAM_A2_Pin|PSRAM_A1_Pin|PSRAM_A3_Pin
                          |PSRAM_A4_Pin|PSRAM_A5_Pin|PSRAM_A7_Pin|PSRAM_A6_Pin
                          |PSRAM_A9_Pin|PSRAM_A8_Pin;
  GPIO_InitStruct.Mode = GPIO_MODE_AF_PP;
  GPIO_InitStruct.Pull = GPIO_NOPULL;
  GPIO_InitStruct.Speed = GPIO_SPEED_FREQ_VERY_HIGH;
  GPIO_InitStruct.Alternate = GPIO_AF12_FMC;
  HAL_GPIO_Init(GPIOF, &GPIO_InitStruct);

  /*Configure GPIO pin : PA9 */
  GPIO_InitStruct.Pin = GPIO_PIN_9;
  GPIO_InitStruct.Mode = GPIO_MODE_INPUT;
  GPIO_InitStruct.Pull = GPIO_NOPULL;
  HAL_GPIO_Init(GPIOA, &GPIO_InitStruct);

  /*Configure GPIO pin : CTP_SCL_Pin */
  GPIO_InitStruct.Pin = CTP_SCL_Pin;
  GPIO_InitStruct.Mode = GPIO_MODE_AF_OD;
  GPIO_InitStruct.Pull = GPIO_PULLUP;
  GPIO_InitStruct.Speed = GPIO_SPEED_FREQ_VERY_HIGH;
  GPIO_InitStruct.Alternate = GPIO_AF4_I2C3;
  HAL_GPIO_Init(CTP_SCL_GPIO_Port, &GPIO_InitStruct);

  /*Configure GPIO pin : LCD_TE_INT_Pin */
  GPIO_InitStruct.Pin = LCD_TE_INT_Pin;
  GPIO_InitStruct.Mode = GPIO_MODE_IT_RISING;
  GPIO_InitStruct.Pull = GPIO_NOPULL;
  HAL_GPIO_Init(LCD_TE_INT_GPIO_Port, &GPIO_InitStruct);

  /*Configure GPIO pins : VCP_RX_Pin VCP_TX_Pin */
  GPIO_InitStruct.Pin = VCP_RX_Pin|VCP_TX_Pin;
  GPIO_InitStruct.Mode = GPIO_MODE_AF_PP;
  GPIO_InitStruct.Pull = GPIO_NOPULL;
  GPIO_InitStruct.Speed = GPIO_SPEED_FREQ_VERY_HIGH;
  GPIO_InitStruct.Alternate = GPIO_AF8_USART6;
  HAL_GPIO_Init(GPIOC, &GPIO_InitStruct);

  /*Configure GPIO pins : ARD_D15_STMOD_I2C2_SCL_Pin ARD_D14_STMOD_I2C2_SDA_Pin */
  GPIO_InitStruct.Pin = ARD_D15_STMOD_I2C2_SCL_Pin|ARD_D14_STMOD_I2C2_SDA_Pin;
  GPIO_InitStruct.Mode = GPIO_MODE_AF_OD;
  GPIO_InitStruct.Pull = GPIO_PULLUP;
  GPIO_InitStruct.Speed = GPIO_SPEED_FREQ_VERY_HIGH;
  GPIO_InitStruct.Alternate = GPIO_AF4_I2C2;
  HAL_GPIO_Init(GPIOH, &GPIO_InitStruct);

  /*Configure GPIO pin : ARD_A3_ADC3_IN8_Pin */
  GPIO_InitStruct.Pin = ARD_A3_ADC3_IN8_Pin;
  GPIO_InitStruct.Mode = GPIO_MODE_ANALOG;
  GPIO_InitStruct.Pull = GPIO_NOPULL;
  HAL_GPIO_Init(ARD_A3_ADC3_IN8_GPIO_Port, &GPIO_InitStruct);

  /*Configure GPIO pin : PF8 */
  GPIO_InitStruct.Pin = GPIO_PIN_8;
  GPIO_InitStruct.Mode = GPIO_MODE_OUTPUT_PP;
  GPIO_InitStruct.Pull = GPIO_NOPULL;
  GPIO_InitStruct.Speed = GPIO_SPEED_FREQ_LOW;
  HAL_GPIO_Init(GPIOF, &GPIO_InitStruct);

  /*Configure GPIO pin : USB_OTGHS_OVCR_INT_Pin */
  GPIO_InitStruct.Pin = USB_OTGHS_OVCR_INT_Pin;
  GPIO_InitStruct.Mode = GPIO_MODE_INPUT;
  GPIO_InitStruct.Pull = GPIO_NOPULL;
  HAL_GPIO_Init(USB_OTGHS_OVCR_INT_GPIO_Port, &GPIO_InitStruct);

  /*Configure GPIO pins : ARD_A4_Pin ARD_A5_Pin ARD_A2_Pin */
  GPIO_InitStruct.Pin = ARD_A4_Pin|ARD_A5_Pin|ARD_A2_Pin;
  GPIO_InitStruct.Mode = GPIO_MODE_ANALOG;
  GPIO_InitStruct.Pull = GPIO_NOPULL;
  HAL_GPIO_Init(GPIOC, &GPIO_InitStruct);

  /*Configure GPIO pins : STMOD_SPI2_MISOs_Pin STMOD__SPI2_MOSIs_Pin */
  GPIO_InitStruct.Pin = STMOD_SPI2_MISOs_Pin|STMOD__SPI2_MOSIs_Pin;
  GPIO_InitStruct.Mode = GPIO_MODE_AF_PP;
  GPIO_InitStruct.Pull = GPIO_NOPULL;
  GPIO_InitStruct.Speed = GPIO_SPEED_FREQ_VERY_HIGH;
  GPIO_InitStruct.Alternate = GPIO_AF5_SPI2;
  HAL_GPIO_Init(GPIOC, &GPIO_InitStruct);

  /*Configure GPIO pin : QSPI_CLK_Pin */
  GPIO_InitStruct.Pin = QSPI_CLK_Pin;
  GPIO_InitStruct.Mode = GPIO_MODE_AF_PP;
  GPIO_InitStruct.Pull = GPIO_NOPULL;
  GPIO_InitStruct.Speed = GPIO_SPEED_FREQ_VERY_HIGH;
  GPIO_InitStruct.Alternate = GPIO_AF9_QUADSPI;
  HAL_GPIO_Init(QSPI_CLK_GPIO_Port, &GPIO_InitStruct);

  /*Configure GPIO pin : CTP_SDA_Pin */
  GPIO_InitStruct.Pin = CTP_SDA_Pin;
  GPIO_InitStruct.Mode = GPIO_MODE_AF_OD;
  GPIO_InitStruct.Pull = GPIO_PULLUP;
  GPIO_InitStruct.Speed = GPIO_SPEED_FREQ_VERY_HIGH;
  GPIO_InitStruct.Alternate = GPIO_AF4_I2C3;
  HAL_GPIO_Init(CTP_SDA_GPIO_Port, &GPIO_InitStruct);

  /*Configure GPIO pin : QSPI_D3_Pin */
  GPIO_InitStruct.Pin = QSPI_D3_Pin;
  GPIO_InitStruct.Mode = GPIO_MODE_AF_PP;
  GPIO_InitStruct.Pull = GPIO_NOPULL;
  GPIO_InitStruct.Speed = GPIO_SPEED_FREQ_VERY_HIGH;
  GPIO_InitStruct.Alternate = GPIO_AF9_QUADSPI;
  HAL_GPIO_Init(QSPI_D3_GPIO_Port, &GPIO_InitStruct);

  /*Configure GPIO pins : ARD_A1_Pin ARD_A0_Pin */
  GPIO_InitStruct.Pin = ARD_A1_Pin|ARD_A0_Pin;
  GPIO_InitStruct.Mode = GPIO_MODE_ANALOG;
  GPIO_InitStruct.Pull = GPIO_NOPULL;
  HAL_GPIO_Init(GPIOA, &GPIO_InitStruct);

  /*Configure GPIO pin : ARD_D13_SPI1_SCK_Pin */
  GPIO_InitStruct.Pin = ARD_D13_SPI1_SCK_Pin;
  GPIO_InitStruct.Mode = GPIO_MODE_AF_PP;
  GPIO_InitStruct.Pull = GPIO_NOPULL;
  GPIO_InitStruct.Speed = GPIO_SPEED_FREQ_VERY_HIGH;
  GPIO_InitStruct.Alternate = GPIO_AF5_SPI1;
  HAL_GPIO_Init(ARD_D13_SPI1_SCK_GPIO_Port, &GPIO_InitStruct);

  /*Configure GPIO pin : ARD_D2_GPIO_Pin */
  GPIO_InitStruct.Pin = ARD_D2_GPIO_Pin;
  GPIO_InitStruct.Mode = GPIO_MODE_OUTPUT_PP;
  GPIO_InitStruct.Pull = GPIO_NOPULL;
  GPIO_InitStruct.Speed = GPIO_SPEED_FREQ_LOW;
  HAL_GPIO_Init(ARD_D2_GPIO_GPIO_Port, &GPIO_InitStruct);

  /*Configure GPIO pins : USB_OTG_HS_ID_Pin SYS_LD_USER2_Pin PB11 */
  GPIO_InitStruct.Pin = USB_OTG_HS_ID_Pin|SYS_LD_USER2_Pin|GPIO_PIN_11;
  GPIO_InitStruct.Mode = GPIO_MODE_OUTPUT_PP;
  GPIO_InitStruct.Pull = GPIO_NOPULL;
  GPIO_InitStruct.Speed = GPIO_SPEED_FREQ_LOW;
  HAL_GPIO_Init(GPIOB, &GPIO_InitStruct);

  /*Configure GPIO pins : USB_OTG_HS_VBUS_Pin USB_OTGFS_OVCR_INT_Pin */
  GPIO_InitStruct.Pin = USB_OTG_HS_VBUS_Pin|USB_OTGFS_OVCR_INT_Pin;
  GPIO_InitStruct.Mode = GPIO_MODE_IT_RISING;
  GPIO_InitStruct.Pull = GPIO_NOPULL;
  HAL_GPIO_Init(GPIOB, &GPIO_InitStruct);

  /*Configure GPIO pin : PMOD_RESET_Pin */
  GPIO_InitStruct.Pin = PMOD_RESET_Pin;
  GPIO_InitStruct.Mode = GPIO_MODE_INPUT;
  GPIO_InitStruct.Pull = GPIO_NOPULL;
  HAL_GPIO_Init(PMOD_RESET_GPIO_Port, &GPIO_InitStruct);

}

void HAL_TIM_PeriodElapsedCallback(TIM_HandleTypeDef *htim)
{
  if (htim->Instance == TIM1) {
    HAL_IncTick();
  }
}

void Error_Handler(void)
{
}

/************************ (C) COPYRIGHT STMicroelectronics *****END OF FILE****/
